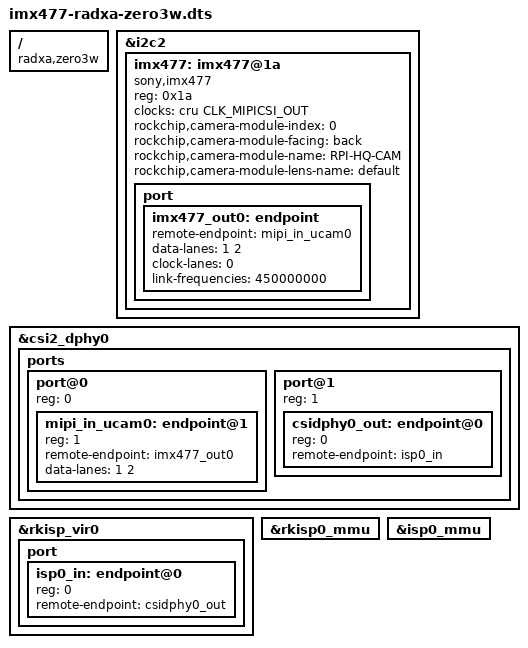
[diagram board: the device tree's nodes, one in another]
// SPDX-License-Identifier: GPL-2.0
/*
 * Device Tree Overlay for Sony IMX477 (Raspberry Pi HQ Camera)
 * on Radxa Zero 3W (RK3566)
 *
 * Camera path: IMX477 → csi2_dphy0 → rkisp_vir0
 *
 * Compile:
 *   dtc -@ -I dts -O dtb -o imx477-radxa-zero3w.dtbo imx477-radxa-zero3w.dts
 *
 * Install:
 *   sudo cp imx477-radxa-zero3w.dtbo /boot/overlays/
 *   Add "dtoverlay=imx477-radxa-zero3w" to /boot/config.txt  (or use rsetup)
 */

/dts-v1/;
/plugin/;

#include <dt-bindings/clock/rk3568-cru.h>
#include <dt-bindings/power/rk3568-power.h>

/ {
	compatible = "radxa,zero3w", "rockchip,rk3566";

	fragment@0 {
		target = <&i2c2>;
		__overlay__ {
			status = "okay";
			#address-cells = <1>;
			#size-cells = <0>;

			imx477: imx477@1a {
				compatible = "sony,imx477";
				reg = <0x1a>;

				/* 24 MHz master clock from RK3566 MIPI CSI clock output */
				clocks = <&cru CLK_MIPICSI_OUT>;
				clock-names = "xclk";

				/*
				 * TODO: Add PWDN and RESET GPIOs if wired on your board.
				 * Example (adjust GPIO bank/pin/polarity to match schematic):
				 *   pwdn-gpios  = <&gpio4 RK_PB3 GPIO_ACTIVE_HIGH>;
				 *   reset-gpios = <&gpio4 RK_PB4 GPIO_ACTIVE_LOW>;
				 */

				/* Rockchip camera module metadata — used by ISP tuning */
				rockchip,camera-module-index = <0>;
				rockchip,camera-module-facing = "back";
				rockchip,camera-module-name = "RPI-HQ-CAM";
				rockchip,camera-module-lens-name = "default";

				port {
					imx477_out0: endpoint {
						remote-endpoint = <&mipi_in_ucam0>;
						data-lanes = <1 2>;
						clock-lanes = <0>;
						link-frequencies = /bits/ 64 <450000000>;
					};
				};
			};
		};
	};

	/* MIPI D-PHY — receives lanes from the sensor */
	fragment@1 {
		target = <&csi2_dphy0>;
		__overlay__ {
			status = "okay";

			ports {
				#address-cells = <1>;
				#size-cells = <0>;

				/* Input port: from sensor */
				port@0 {
					reg = <0>;
					#address-cells = <1>;
					#size-cells = <0>;

					mipi_in_ucam0: endpoint@1 {
						reg = <1>;
						remote-endpoint = <&imx477_out0>;
						data-lanes = <1 2>;
					};
				};

				/* Output port: to ISP */
				port@1 {
					reg = <1>;
					#address-cells = <1>;
					#size-cells = <0>;

					csidphy0_out: endpoint@0 {
						reg = <0>;
						remote-endpoint = <&isp0_in>;
					};
				};
			};
		};
	};

	/* ISP virtual device 0 */
	fragment@2 {
		target = <&rkisp_vir0>;
		__overlay__ {
			status = "okay";

			port {
				#address-cells = <1>;
				#size-cells = <0>;

				isp0_in: endpoint@0 {
					reg = <0>;
					remote-endpoint = <&csidphy0_out>;
				};
			};
		};
	};

	/* ISP MMU must be enabled for ISP to function */
	fragment@3 {
		target = <&rkisp0_mmu>;
		__overlay__ {
			status = "okay";
		};
	};

	/* Enable the ISP power domain */
	fragment@4 {
		target = <&isp0_mmu>;
		__overlay__ {
			status = "okay";
		};
	};
};
